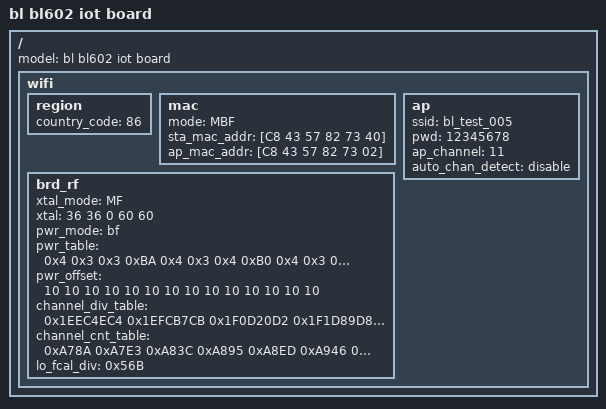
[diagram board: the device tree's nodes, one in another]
/dts-v1/;
/include/ "bl602_base.dtsi";

/ {
    model = "bl bl602 iot board";
    wifi {
        #address-cells = <1>;
        #size-cells = <1>;
        region {
            country_code = <86>;
        };
        mac {
            mode = "MBF";
            sta_mac_addr = [C8 43 57 82 73 40];
            ap_mac_addr = [C8 43 57 82 73 02];
        };
        ap {
            ssid = "bl_test_005";
            pwd = "12345678";
            ap_channel = <11>;
            auto_chan_detect = "disable";
        };
        brd_rf {
            xtal_mode = "MF";
            xtal = <36 36 0 60 60>;
            pwr_mode = "bf";
            pwr_table = <0x4 0x3 0x3 0xBA 0x4 0x3 0x4 0xB0 0x4 0x3 0x5 0xA7 0x3 0x3 0x0 0x9F 0x3 0x3 0x1 0x95 0x3 0x3 0x2 0x8C 0x3 0x3 0x3 0x81 0x3 0x3 0x4 0x77 0x3 0x3 0x5 0x6E 0x2 0x3 0x0 0x65 0x2 0x3 0x1 0x5B 0x2 0x3 0x2 0x52 0x2 0x3 0x3 0x48 0x2 0x3 0x4 0x3E 0x2 0x3 0x5 0x34 0x1 0x3 0x3 0xA>;
            pwr_offset = <10 10 10 10 10 10 10 10 10 10 10 10 10 10>;
            channel_div_table = <0x1EEC4EC4 0x1EFCB7CB 0x1F0D20D2 0x1F1D89D8 0x1F2DF2DF 0x1F3E5BE5 0x1F4EC4EC 0x1F5F2DF2 0x1F6F96F9 0x1F800000 0x1F906906 0x1FA0D20D 0x1FB13B13 0x1FD89D89 0x201F81F8>;
            channel_cnt_table = <0xA78A 0xA7E3 0xA83C 0xA895 0xA8ED 0xA946 0xA99F 0xA9F8 0xAA51 0xAAAA 0xAB03 0xAB5C 0xABB5 0xAC8A>;
            lo_fcal_div = <0x56B>;
        };
    };
};
